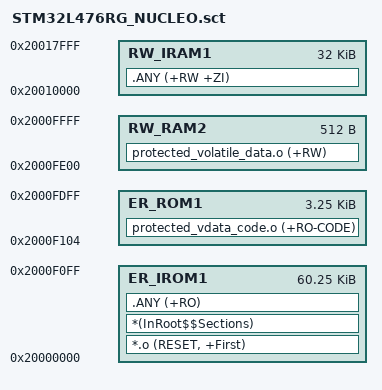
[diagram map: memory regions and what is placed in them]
; *************************************************************
; *** Scatter-Loading Description File generated by uVision ***
; *************************************************************

LR_IROM1 0x20000000 0x0000F100  {    ; load region size_region
  ER_IROM1 0x20000000 0x0000F100  {  ; load address = execution address
   *.o (RESET, +First)
   *(InRoot$$Sections)
   .ANY (+RO)
  }
  RW_IRAM1 0x20010000 0x00008000  {  ; RW data
   .ANY (+RW +ZI)
  }
  ; /**********************************************************/
  ; /*  RW_RAM2: used to locate data in volatile data segment */
  ; /**********************************************************/  
  RW_RAM2 0x2000FE00 0x0200{  ; RW data
   protected_volatile_data.o (+RW)
  }  
}

; /****************************************************************************/
; /*                                                                          */
; /*          LR_ROM1: used to locate code in protected code segment          */
; /*                                                                          */
; /****************************************************************************/
; /* Note that the protected code segment doesn't exactly start at the 
;    starting address used to configure de Firewall.
;    This allows to locate the function used to open the Firewall at the
;    correct address to obey the call gate sequence */
LR_ROM1 0x2000F104 0x0000CFC {
  ER_ROM1 0x2000F104 0x0000CFC  {  ; load address = execution address
    protected_vdata_code.o (+RO-CODE)
	
  }
}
